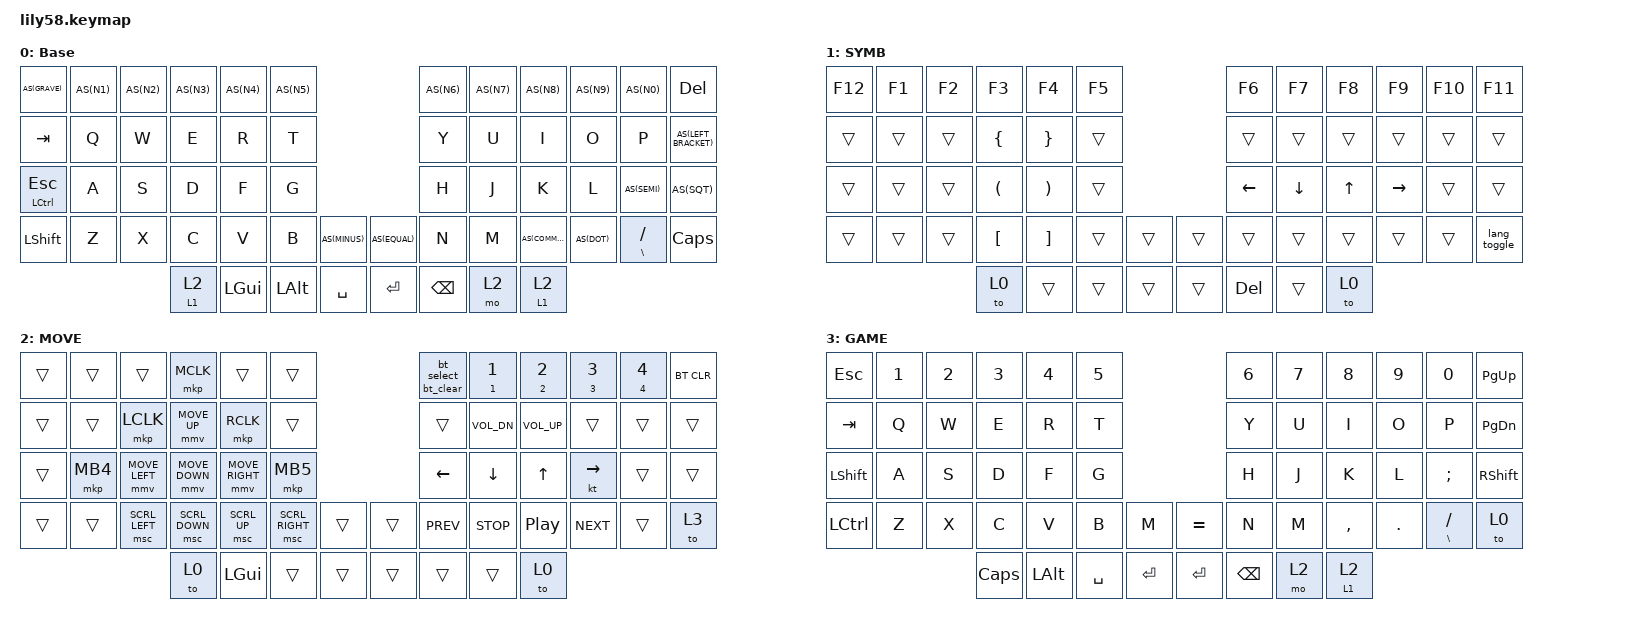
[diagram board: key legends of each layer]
/* Copyright (c) 2020 The ZMK Contributors
 *
 * SPDX-License-Identifier: MIT
 */

#include <behaviors.dtsi>
#include <dt-bindings/zmk/bt.h>
#include <dt-bindings/zmk/keys.h>
#include <dt-bindings/zmk/keys.h>
#include <dt-bindings/zmk/pointing.h>

#define ZMK_POINTING_DEFAULT_MOVE_VAL 1000
#define AS(keycode) &as LS(keycode) keycode


/ {
    macros {
        lang_toggle: lang_toggle {
            compatible = "zmk,behavior-macro";
            #binding-cells = <0>;
            bindings = <&macro_press &kp LSHFT &kp RSHFT>
                     , <&macro_pause_for_release>
                     , <&macro_release &kp LSHFT &kp RSHFT>;
        };

        bt_select: bt_select {
            compatible = "zmk,behavior-macro-one-param";
            #binding-cells = <1>;
            bindings
                = <&macro_param_1to2>
                , <&bt BT_SEL MACRO_PLACEHOLDER>;
        };

        // Reset a specific profile: select it, then clear its bond.
        bt_clear: bt_clear {
            compatible = "zmk,behavior-macro-one-param";
            #binding-cells = <1>;
            bindings
                = <&macro_param_1to2>
                , <&bt BT_SEL MACRO_PLACEHOLDER>
                , <&bt BT_CLR>;
        };
    };

    behaviors {

        as: auto_shift {
            compatible = "zmk,behavior-hold-tap";
            label = "AUTO_SHIFT";
            #binding-cells = <2>;
            tapping_term_ms = <135>;
            quick_tap_ms = <0>;
            flavor = "tap-preferred";
            bindings = <&kp>, <&kp>;
        };

        thk: zmk,behavior-hold-tap {
            compatible = "zmk,behavior-hold-tap";
            #binding-cells = <2>;
            bindings = <&kp>, <&kp>;

            tapping-term-ms = <100>;
            hold-while-undecided;
        };


        th_layer_switch: zmk,behavior-hold-tap-layer {
            compatible = "zmk,behavior-hold-tap";
            #binding-cells = <2>;
            bindings = <&mo>, <&tog>;

            tapping-term-ms = <200>;
            hold-while-undecided;
        };

        // Tap = select BT profile, hold = reset that profile's bond.
        bt_sel_clr: bt_sel_clr {
            compatible = "zmk,behavior-hold-tap";
            label = "BT_SEL_CLR";
            #binding-cells = <2>;
            tapping-term-ms = <3000>;
            flavor = "hold-preferred";
            bindings = <&bt_clear>, <&bt_select>;
        };
    };

    keymap {
        compatible = "zmk,keymap";

        default_layer {
            // ------------------------------------------------------------------------------------------------------------
            // |  ESC  |  1  |  2  |  3   |  4   |  5   |                   |  6   |  7    |  8    |  9   |   0   |   `   |
            // |  TAB  |  Q  |  W  |  E   |  R   |  T   |                   |  Y   |  U    |  I    |  O   |   P   |   -   |
            // |  CTRL |  A  |  S  |  D   |  F   |  G   |                   |  H   |  J    |  K    |  L   |   ;   |   '   |
            // | SHIFT |  Z  |  X  |  C   |  V   |  B   |   "["  |  |  "]"  |  N   |  M    |  ,    |  .   |   /   | SHIFT |
            //                     | ALT  | GUI  | LOWER|  SPACE |  | ENTER |  F1  | BSPC  | GUI   |
            //

            display-name = "Base";
            bindings = <
AS(GRAVE)          AS(N1) AS(N2) AS(N3) AS(N4) AS(N5)                                                              AS(N6)  AS(N7) AS(N8)  AS(N9)  AS(N0)   &kp DEL
&kp TAB            &kp Q         &kp W   &kp E                 &kp R         &kp T                                 &kp Y     &kp U   &kp I                 &kp O    &kp P                 AS(LEFT_BRACKET)
&thk LCTRL ESCAPE  &kp A         &kp S   &kp D                 &kp F         &kp G                                 &kp H     &kp J   &kp K                 &kp L    AS(SEMI)              AS(SQT)
&kp LSHFT          &kp Z         &kp X   &kp C                 &kp V         &kp B         AS(MINUS)    AS(EQUAL)  &kp N     &kp M   AS(COMMA)             AS(DOT)  &thk BACKSLASH SLASH  &kp CAPS
                                         &th_layer_switch 1 2  &kp LEFT_GUI  &kp LEFT_ALT  &kp SPACE    &kp RET    &kp BSPC  &mo 2   &th_layer_switch 1 2
            >;
        };

        SYMB {
            bindings = <
&kp F12  &kp F1  &kp F2  &kp F3                &kp F4                 &kp F5                    &kp F6    &kp F7    &kp F8  &kp F9     &kp F10  &kp F11
&trans   &trans  &trans  &kp LEFT_BRACE        &kp RIGHT_BRACE        &trans                    &trans    &trans    &trans  &trans     &trans   &trans
&trans   &trans  &trans  &kp LEFT_PARENTHESIS  &kp RIGHT_PARENTHESIS  &trans                    &kp LEFT  &kp DOWN  &kp UP  &kp RIGHT  &trans   &trans
&trans   &trans  &trans  &kp LEFT_BRACKET      &kp RIGHT_BRACKET      &trans  &trans    &trans  &trans    &trans    &trans  &trans     &trans   &lang_toggle
                         &to 0                 &trans                 &trans  &trans    &trans  &kp DEL   &trans    &to 0
            >;
        };

        MOVE {
            bindings = <
&trans  &trans    &trans          &mkp MCLK       &trans           &trans                             &bt_sel_clr 0 0  &bt_sel_clr 1 1  &bt_sel_clr 2 2   &bt_sel_clr 3 3  &bt_sel_clr 4 4  &bt BT_CLR
&trans  &trans    &mkp LCLK       &mmv MOVE_UP    &mkp RCLK        &trans                             &trans        &kp C_VOL_DN  &kp C_VOL_UP      &trans        &trans        &trans
&trans  &mkp MB4  &mmv MOVE_LEFT  &mmv MOVE_DOWN  &mmv MOVE_RIGHT  &mkp MB5                           &kp LEFT      &kp DOWN      &kp UP            &kt RIGHT     &trans        &trans
&trans  &trans    &msc SCRL_LEFT  &msc SCRL_DOWN  &msc SCRL_UP     &msc SCRL_RIGHT  &trans    &trans  &kp C_PREV    &kp C_STOP    &kp C_PLAY_PAUSE  &kp C_NEXT    &trans        &to 3
                                  &to 0           &kp LGUI         &trans           &trans    &trans  &trans        &trans        &to 0
            >;
        };

        GAME {
            bindings = <
&kp ESC            &kp NUMBER_1  &kp N2  &kp N3                &kp N4        &kp N5                                &kp N6    &kp N7  &kp N8                &kp N9   &kp N0                &kp PG_UP
&kp TAB            &kp Q         &kp W   &kp E                 &kp R         &kp T                                 &kp Y     &kp U   &kp I                 &kp O    &kp P                 &kp PG_DN
&kp LSHFT          &kp A         &kp S   &kp D                 &kp F         &kp G                                 &kp H     &kp J   &kp K                 &kp L    &kp SEMI              &kp RSHFT
&kp LCTRL          &kp Z         &kp X   &kp C                 &kp V         &kp B         &kp M        &kp EQUAL  &kp N     &kp M   &kp COMMA             &kp DOT  &thk BACKSLASH SLASH  &to 0
                                         &kp CAPSLOCK  &kp LALT &kp SPACE  &kp RET    &kp RET    &kp BSPC  &mo 2   &th_layer_switch 1 2
            >;
        };
    };
};
